VERSION ""

BO_ 274923520 DriverDoorStatus: 1 GMLAN
 SG_ DriverDoorOpened : 0|1@0+ (1,0) [0|0] ""  NEO

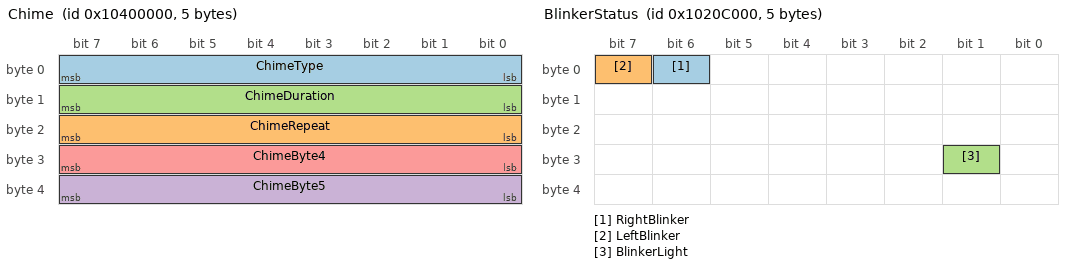
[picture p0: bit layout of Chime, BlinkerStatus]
BO_ 272629760 Chime: 5 NEO
 SG_ ChimeType : 7|8@0+ (1,0) [0|0] ""  GMLAN
 SG_ ChimeRepeat : 23|8@0+ (1,0) [0|0] ""  GMLAN
 SG_ ChimeDuration : 15|8@0+ (1,0) [0|0] ""  GMLAN
 SG_ ChimeByte5 : 39|8@0+ (1,0) [0|0] ""  GMLAN
 SG_ ChimeByte4 : 31|8@0+ (1,0) [0|0] ""  GMLAN

BO_ 270581760 BlinkerStatus: 5 GMLAN
 SG_ RightBlinker : 6|1@0+ (1,0) [0|0] ""  NEO
 SG_ LeftBlinker : 7|1@0+ (1,0) [0|0] ""  NEO
 SG_ BlinkerLight : 25|1@0+ (1,0) [0|0] ""  NEO

BO_ 270794752 SteeringWheelAngle: 8 GMLAN
 SG_ SteeringWheelAngle : 39|16@0- (0.0625,0) [-540|540] "deg"  NEO

BO_ 271368192 GearShifter: 8 GMLAN
 SG_ GearShifter : 17|2@0+ (1,0) [0|3] ""  NEO

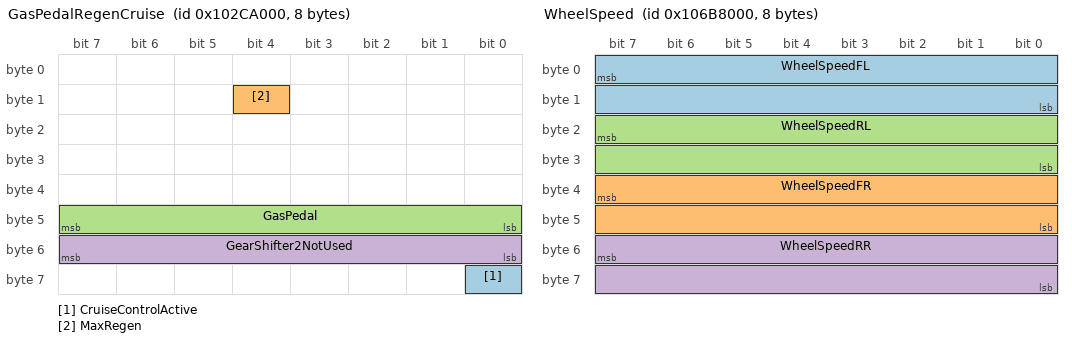
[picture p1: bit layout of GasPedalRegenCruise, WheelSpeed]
BO_ 271360000 GasPedalRegenCruise: 8 GMLAN
 SG_ CruiseControlActive : 56|1@0+ (1,0) [0|0] ""  GMLAN
 SG_ MaxRegen : 12|1@0+ (1,0) [0|1] ""  GMLAN,NEO
 SG_ GasPedal : 47|8@0+ (1,0) [0|254] ""  GMLAN,NEO
 SG_ GearShifter2NotUsed : 55|8@0+ (1,0) [0|255] ""  GMLAN,NEO

BO_ 270860288 BrakePedal: 2 GMLAN
 SG_ BrakeLevel : 2|2@0+ (1,0) [0|3] ""  NEO
 SG_ BrakeSensor : 15|8@0+ (1,0) [0|255] ""  NEO

BO_ 275480576 WheelSpeed: 8 GMLAN
 SG_ WheelSpeedFL : 7|16@0+ (0.01,0) [0|70] "yd/s"  NEO
 SG_ WheelSpeedFR : 39|16@0+ (0.01,0) [0|70] "yd/s"  NEO
 SG_ WheelSpeedRL : 23|16@0+ (0.01,0) [0|70] "yd/s"  NEO
 SG_ WheelSpeedRR : 55|16@0+ (0.01,0) [0|70] "yd/s"  NEO

BO_ 270598144 VehicleSpeed: 8 GMLAN
 SG_ VehicleSpeed1 : 7|16@0+ (0.01,0) [0|100] "mph"  NEO
 SG_ VehicleSpeed2 : 39|16@0+ (0.01,0) [0|100] "mph"  NEO

BO_ 276135936 CruiseButtons: 3 GMLAN
 SG_ CruiseButtons : 3|3@0+ (1,0) [0|12] ""  NEO

BO_ 276127744 CruiseButtons2: 1 GMLAN
 SG_ LKAGapButton : 1|2@0+ (1,0) [0|2] ""  NEO

BO_ 275955897 LeftRadar: 2 GMLAN
 SG_ BSM_Indicator_Light : 4|1@0+ (1,0) [0|1] "" XXX

BO_ 275980379 RightRadar: 2 GMLAN
 SG_ BSM_Indicator_Light : 0|1@0+ (1,0) [0|1] "" XXX

BA_DEF_  "UseGMParameterIDs" INT 0 0;
BA_DEF_  "ProtocolType" STRING ;
BA_DEF_  "BusType" STRING ;
BA_DEF_DEF_  "UseGMParameterIDs" 1;
BA_DEF_DEF_  "ProtocolType" "GMLAN";
BA_DEF_DEF_  "BusType" "";
BA_ "BusType" "CAN";
BU_: K182_PACM K43_PSCM K17_EBCM NEO K124_ASCM

CM_ SG_ 3 STEER_DIRECTION "0 = left, 1 = right";
CM_ SG_ 5 BRAKE_POSITION "computer and driver";
CM_ SG_ 5 BRAKE_PRESSED "computer and driver";
CM_ SG_ 261 GAS_PEDAL "user gas input";
CM_ SG_ 261 COMBINED_GAS "computer and driver gas";
VAL_ 780 CRUISE_SPEED 255 "no_speed" 252 "stopped";
VAL_ 780 HUD_LEAD 3 "acc_off" 2 "solid_car" 1 "dashed_car" 0 "no_car";
VAL_ 884 DASHBOARD_ALERT 0 "none" 51 "acc_problem" 55 "cmbs_problem" 75 "key_not_detected" 79 "fasten_seatbelt" 111 "lkas_problem" 131 "brake_system_problem" 132 "brake_hold_problem" 139 "tbd" 161 "door_open";
VAL_ 891 WIPERS 4 "High" 2 "Low" 0 "Off";

VAL_ 399 STEER_STATUS 6 "tmp_fault" 5 "fault_1" 4 "no_torque_alert_2" 3 "low_speed_lockout" 2 "no_torque_alert_1" 0 "normal";

VAL_ 829 BEEP 3 "single_beep" 2 "triple_beep" 1 "repeated_beep" 0 "no_beep";

VAL_ 401 GEAR_SHIFTER 32 "L" 16 "S" 8 "D" 4 "N" 2 "R" 1 "P" ;
VAL_ 401 GEAR 7 "L" 10 "S" 4 "D" 3 "N" 2 "R" 1 "P" ;
VAL_ 545 ECON_ON_2 0 "off" 3 "on" ;
VAL_ 662 CRUISE_BUTTONS 7 "tbd" 6 "tbd" 5 "tbd" 4 "accel_res" 3 "decel_set" 2 "cancel" 1 "main" 0 "none" ;
VAL_ 662 CRUISE_SETTING 3 "distance_adj" 2 "tbd" 1 "lkas_button" 0 "none" ;
